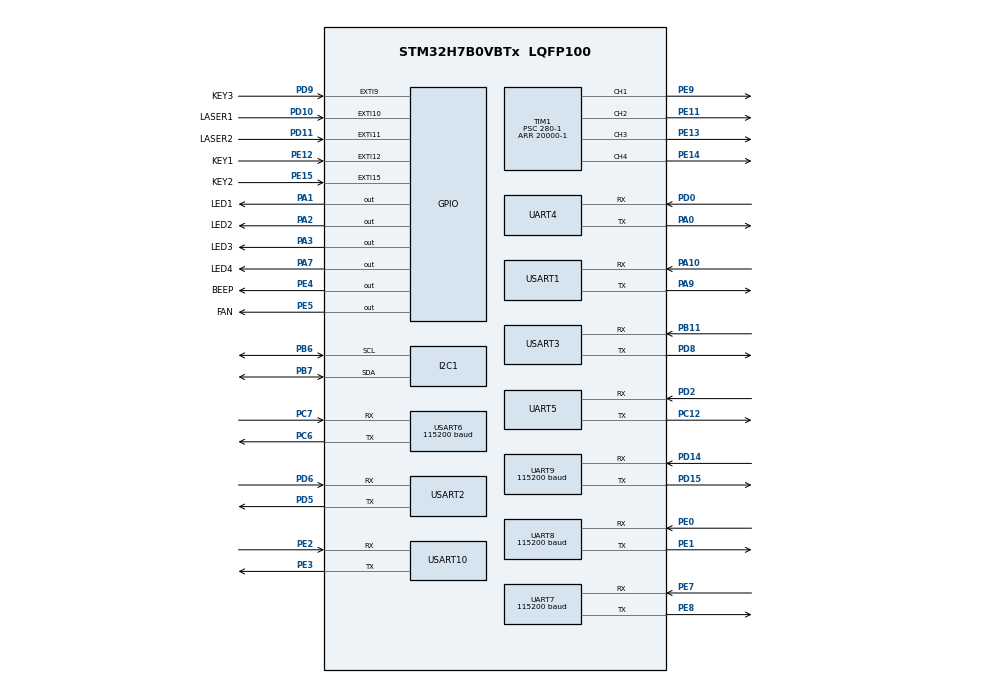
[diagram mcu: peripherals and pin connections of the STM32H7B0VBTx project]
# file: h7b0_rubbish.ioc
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I2C1.Timing=0x20B0CCFF
Mcu.Family=STM32H7
Mcu.Name=STM32H7B0VBTx
Mcu.Package=LQFP100
NVIC.EXTI15_10_IRQn=true\:0\:0\:false\:false\:true\:true\:true\:true
NVIC.EXTI9_5_IRQn=true\:0\:0\:false\:false\:true\:true\:true\:true
NVIC.PriorityGroup=NVIC_PRIORITYGROUP_4
NVIC.UART4_IRQn=true\:0\:0\:false\:false\:true\:true\:true\:true
NVIC.UART5_IRQn=true\:0\:0\:false\:false\:true\:true\:true\:true
NVIC.UART7_IRQn=true\:0\:0\:false\:false\:true\:true\:true\:true
NVIC.UART8_IRQn=true\:0\:0\:false\:false\:true\:true\:true\:true
NVIC.UART9_IRQn=true\:0\:0\:false\:false\:true\:true\:true\:true
NVIC.USART10_IRQn=true\:0\:0\:false\:false\:true\:true\:true\:true
NVIC.USART1_IRQn=true\:0\:0\:false\:false\:true\:true\:true\:true
NVIC.USART2_IRQn=true\:0\:0\:false\:false\:true\:true\:true\:true
NVIC.USART3_IRQn=true\:0\:0\:false\:false\:true\:true\:true\:true
NVIC.USART6_IRQn=true\:0\:0\:false\:false\:true\:true\:true\:true
PA0.GPIO_PuPd=GPIO_PULLUP
PA0.Mode=Asynchronous
PA0.Signal=UART4_TX
PA1.GPIO_Label=LED1
PA1.Signal=GPIO_Output
PA10.Mode=Asynchronous
PA10.Signal=USART1_RX
PA13.Mode=Serial_Wire
PA13.Signal=DEBUG_JTMS-SWDIO
PA14.Mode=Serial_Wire
PA14.Signal=DEBUG_JTCK-SWCLK
PA15.Signal=S_TIM2_CH1_ETR
PA2.GPIO_Label=LED2
PA2.Signal=GPIO_Output
PA3.GPIO_Label=LED3
PA3.Signal=GPIO_Output
PA5.Signal=SPI1_SCK
PA6.Signal=SPI1_MISO
PA7.GPIO_Label=LED4
PA7.Signal=GPIO_Output
PA9.Mode=Asynchronous
PA9.Signal=USART1_TX
PB0.Signal=S_TIM3_CH3
PB1.Signal=S_TIM3_CH4
PB11.Mode=Asynchronous
PB11.Signal=USART3_RX
PB6.Mode=I2C
PB6.Signal=I2C1_SCL
PB7.Mode=I2C
PB7.Signal=I2C1_SDA
PC12.GPIO_PuPd=GPIO_PULLUP
PC12.Mode=Asynchronous
PC12.Signal=UART5_TX
PC14-OSC32_IN.Mode=LSE-External-Oscillator
PC14-OSC32_IN.Signal=RCC_OSC32_IN
PC15-OSC32_OUT.Mode=LSE-External-Oscillator
PC15-OSC32_OUT.Signal=RCC_OSC32_OUT
PC6.Mode=Asynchronous
PC6.Signal=USART6_TX
PC7.Mode=Asynchronous
PC7.Signal=USART6_RX
PD0.GPIO_PuPd=GPIO_PULLUP
PD0.Mode=Asynchronous
PD0.Signal=UART4_RX
PD10.GPIO_Label=LASER1
PD10.GPIO_PuPd=GPIO_NOPULL
PD10.Signal=GPXTI10
PD11.GPIO_Label=LASER2
PD11.GPIO_PuPd=GPIO_NOPULL
PD11.Signal=GPXTI11
PD14.GPIO_PuPd=GPIO_PULLUP
PD14.Mode=Asynchronous
PD14.Signal=UART9_RX
PD15.GPIO_PuPd=GPIO_PULLUP
PD15.Mode=Asynchronous
PD15.Signal=UART9_TX
PD2.GPIO_PuPd=GPIO_PULLUP
PD2.Mode=Asynchronous
PD2.Signal=UART5_RX
PD5.Mode=Asynchronous
PD5.Signal=USART2_TX
PD6.Mode=Asynchronous
PD6.Signal=USART2_RX
PD7.Signal=SPI1_MOSI
PD8.Mode=Asynchronous
PD8.Signal=USART3_TX
PD9.GPIO_Label=KEY3
PD9.GPIO_ModeDefaultEXTI=GPIO_MODE_IT_FALLING
PD9.GPIO_PuPd=GPIO_PULLUP
PD9.Signal=GPXTI9
PE0.GPIO_PuPd=GPIO_PULLUP
PE0.Mode=Asynchronous
PE0.Signal=UART8_RX
PE1.GPIO_PuPd=GPIO_PULLUP
PE1.Mode=Asynchronous
PE1.Signal=UART8_TX
PE11.Signal=S_TIM1_CH2
PE12.GPIO_Label=KEY1
PE12.GPIO_ModeDefaultEXTI=GPIO_MODE_IT_FALLING
PE12.GPIO_PuPd=GPIO_PULLUP
PE12.Signal=GPXTI12
PE13.Signal=S_TIM1_CH3
PE14.Signal=S_TIM1_CH4
PE15.GPIO_Label=KEY2
PE15.GPIO_ModeDefaultEXTI=GPIO_MODE_IT_FALLING
PE15.GPIO_PuPd=GPIO_PULLUP
PE15.Signal=GPXTI15
PE2.Mode=Asynchronous
PE2.Signal=USART10_RX
PE3.Mode=Asynchronous
PE3.Signal=USART10_TX
PE4.GPIO_Label=BEEP
PE4.GPIO_PuPd=GPIO_PULLDOWN
PE4.Signal=GPIO_Output
PE5.GPIO_Label=FAN
PE5.GPIO_PuPd=GPIO_PULLUP
PE5.Signal=GPIO_Output
PE7.GPIO_PuPd=GPIO_PULLUP
PE7.Mode=Asynchronous
PE7.Signal=UART7_RX
PE8.GPIO_PuPd=GPIO_PULLUP
PE8.Mode=Asynchronous
PE8.Signal=UART7_TX
PE9.Signal=S_TIM1_CH1
PH0-OSC_IN.Mode=HSE-External-Oscillator
PH0-OSC_IN.Signal=RCC_OSC_IN
PH1-OSC_OUT.Mode=HSE-External-Oscillator
PH1-OSC_OUT.Signal=RCC_OSC_OUT
ProjectManager.HeapSize=0x400
ProjectManager.StackSize=0x800
ProjectManager.TargetToolchain=STM32CubeIDE
RCC.ADCFreq_Value=129000000
RCC.APB1Freq_Value=140000000
RCC.APB2Freq_Value=140000000
RCC.APB3Freq_Value=140000000
RCC.APB4Freq_Value=140000000
RCC.CDPPRE=RCC_APB3_DIV2
RCC.CDPPRE1=RCC_APB1_DIV2
RCC.CDPPRE2=RCC_APB2_DIV2
RCC.CortexFreq_Value=280000000
RCC.DIVM1=16
RCC.DIVN1=140
RCC.HCLKFreq_Value=280000000
RCC.PLL2FRACN=0
RCC.PLL3FRACN=0
RCC.PLLFRACN=0
RCC.SRDPPRE=RCC_APB4_DIV2
RCC.SYSCLKFreq_VALUE=280000000
RCC.SYSCLKSource=RCC_SYSCLKSOURCE_PLLCLK
RCC.USART16CLockSelection=RCC_USART16910CLKSOURCE_HSI
RCC.USART234578CLockSelection=RCC_USART234578CLKSOURCE_HSI
RCC.USBFreq_Value=280000000
SH.S_TIM1_CH1.0=TIM1_CH1,PWM Generation1 CH1
SH.S_TIM1_CH2.0=TIM1_CH2,PWM Generation2 CH2
SH.S_TIM1_CH3.0=TIM1_CH3,PWM Generation3 CH3
SH.S_TIM1_CH4.0=TIM1_CH4,PWM Generation4 CH4
SH.S_TIM2_CH1_ETR.0=TIM2_CH1
SH.S_TIM3_CH3.0=TIM3_CH3
SH.S_TIM3_CH4.0=TIM3_CH4
TIM1.Channel-PWM\ Generation1\ CH1=TIM_CHANNEL_1
TIM1.Channel-PWM\ Generation2\ CH2=TIM_CHANNEL_2
TIM1.Channel-PWM\ Generation3\ CH3=TIM_CHANNEL_3
TIM1.Channel-PWM\ Generation4\ CH4=TIM_CHANNEL_4
TIM1.Period=20000-1
TIM1.Prescaler=280-1
TIM1.Pulse-PWM\ Generation1\ CH1=1500
TIM1.Pulse-PWM\ Generation2\ CH2=1500
TIM1.Pulse-PWM\ Generation3\ CH3=1500
TIM1.Pulse-PWM\ Generation4\ CH4=1500
TIM15.AutoReloadPreload=TIM_AUTORELOAD_PRELOAD_ENABLE
TIM15.Period=1000-1
TIM15.Prescaler=280-1
TIM16.AutoReloadPreload=TIM_AUTORELOAD_PRELOAD_ENABLE
TIM16.Period=2000-1
TIM16.Prescaler=280-1
TIM17.Period=10000-1
TIM17.Prescaler=280-1
UART7.BaudRate=115200
UART8.BaudRate=115200
UART9.BaudRate=115200
USART1.VirtualMode-Asynchronous=VM_ASYNC
USART10.VirtualMode=VM_ASYNC
USART2.VirtualMode-Asynchronous=VM_ASYNC
USART3.VirtualMode-Asynchronous=VM_ASYNC
USART6.BaudRate=115200
USART6.VirtualMode=VM_ASYNC
VP_TIM15_VS_ClockSourceINT.Mode=Internal
VP_TIM16_VS_ClockSourceINT.Mode=Enable_Timer
VP_TIM17_VS_ClockSourceINT.Mode=Enable_Timer
VP_TIM1_VS_ClockSourceINT.Mode=Internal
board=custom

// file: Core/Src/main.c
/* USER CODE BEGIN Header */
/**
  ******************************************************************************
  * @file           : main.c
  * @brief          : Main program body
  ******************************************************************************
  * @attention
  *
  * Copyright (c) 2023 STMicroelectronics.
  * All rights reserved.
  *
  * This software is licensed under terms that can be found in the LICENSE file
  * in the root directory of this software component.
  * If no LICENSE file comes with this software, it is provided AS-IS.
  *
  ******************************************************************************
  */
/* USER CODE END Header */
#include "main.h"
#include "i2c.h"
#include "tim.h"
#include "usart.h"
#include "gpio.h"

/* USER CODE BEGIN Includes */
#include <stdlib.h>
#include "../../User/user.h"
/* USER CODE END Includes */

void SystemClock_Config(void);

int main(void)
{

  /* MCU Configuration--------------------------------------------------------*/

  /* Reset of all peripherals, Initializes the Flash interface and the Systick. */
  HAL_Init();

  /* Configure the system clock */
  SystemClock_Config();

  /* Initialize all configured peripherals */
  MX_GPIO_Init();
  MX_USART1_UART_Init();
  MX_USART2_UART_Init();
  MX_UART8_Init();
  MX_USART6_UART_Init();
  MX_UART7_Init();
  MX_UART9_Init();
  MX_I2C1_Init();
  MX_TIM1_Init();
  MX_TIM15_Init();
  MX_USART3_UART_Init();
  MX_UART4_Init();
  MX_TIM17_Init();
  MX_UART5_Init();
  MX_USART10_UART_Init();
  MX_TIM16_Init();
  /* USER CODE BEGIN 2 */
    setup();
  /* USER CODE END 2 */

  /* Infinite loop */
  /* USER CODE BEGIN WHILE */
    while (1) {
        loop();
    /* USER CODE END WHILE */

    }
}

void SystemClock_Config(void)
{
  RCC_OscInitTypeDef RCC_OscInitStruct = {0};
  RCC_ClkInitTypeDef RCC_ClkInitStruct = {0};

  /*AXI clock gating */
  RCC->CKGAENR = 0xFFFFFFFF;

  /** Supply configuration update enable
  */
  HAL_PWREx_ConfigSupply(PWR_LDO_SUPPLY);

  /** Configure the main internal regulator output voltage
  */
  __HAL_PWR_VOLTAGESCALING_CONFIG(PWR_REGULATOR_VOLTAGE_SCALE0);

  while(!__HAL_PWR_GET_FLAG(PWR_FLAG_VOSRDY)) {}

  /** Initializes the RCC Oscillators according to the specified parameters
  * in the RCC_OscInitTypeDef structure.
  */
  RCC_OscInitStruct.OscillatorType = RCC_OSCILLATORTYPE_HSI;
  RCC_OscInitStruct.HSIState = RCC_HSI_DIV1;
  RCC_OscInitStruct.HSICalibrationValue = 64;
  RCC_OscInitStruct.PLL.PLLState = RCC_PLL_ON;
  RCC_OscInitStruct.PLL.PLLSource = RCC_PLLSOURCE_HSI;
  RCC_OscInitStruct.PLL.PLLM = 16;
  RCC_OscInitStruct.PLL.PLLN = 140;
  RCC_OscInitStruct.PLL.PLLP = 2;
  RCC_OscInitStruct.PLL.PLLQ = 2;
  RCC_OscInitStruct.PLL.PLLR = 2;
  RCC_OscInitStruct.PLL.PLLRGE = RCC_PLL1VCIRANGE_2;
  RCC_OscInitStruct.PLL.PLLVCOSEL = RCC_PLL1VCOWIDE;
  RCC_OscInitStruct.PLL.PLLFRACN = 0;
  if (HAL_RCC_OscConfig(&RCC_OscInitStruct) != HAL_OK)
  {
    Error_Handler();
  }

  /** Initializes the CPU, AHB and APB buses clocks
  */
  RCC_ClkInitStruct.ClockType = RCC_CLOCKTYPE_HCLK|RCC_CLOCKTYPE_SYSCLK
                              |RCC_CLOCKTYPE_PCLK1|RCC_CLOCKTYPE_PCLK2
                              |RCC_CLOCKTYPE_D3PCLK1|RCC_CLOCKTYPE_D1PCLK1;
  RCC_ClkInitStruct.SYSCLKSource = RCC_SYSCLKSOURCE_PLLCLK;
  RCC_ClkInitStruct.SYSCLKDivider = RCC_SYSCLK_DIV1;
  RCC_ClkInitStruct.AHBCLKDivider = RCC_HCLK_DIV1;
  RCC_ClkInitStruct.APB3CLKDivider = RCC_APB3_DIV2;
  RCC_ClkInitStruct.APB1CLKDivider = RCC_APB1_DIV2;
  RCC_ClkInitStruct.APB2CLKDivider = RCC_APB2_DIV2;
  RCC_ClkInitStruct.APB4CLKDivider = RCC_APB4_DIV2;

  if (HAL_RCC_ClockConfig(&RCC_ClkInitStruct, FLASH_LATENCY_7) != HAL_OK)
  {
    Error_Handler();
  }
}

void Error_Handler(void)
{
    __disable_irq();
    while (1) {
    }
}
